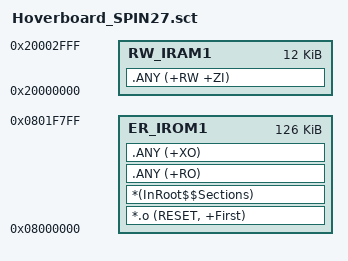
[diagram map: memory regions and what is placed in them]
; ***********************************************************************
; *** Scatter-Loading Description File generated by uv2csolution ***
; ***********************************************************************

; 0x0801F800-0x0801FFFF is reserved for the simulated EEPROM (sim_eeprom.c),
; so code is limited to 0x1F800 bytes and the link fails rather than overlapping it.
LR_IROM1 0x08000000 0x0001F800 {    ; load region size_region
  ER_IROM1 0x08000000 0x0001F800 {  ; load address = execution address
   *.o (RESET, +First)
   *(InRoot$$Sections)
   .ANY (+RO)
   .ANY (+XO)
  }
  RW_IRAM1 0x20000000 0x00003000 {  ; RW data
   .ANY (+RW +ZI)
  }
}

